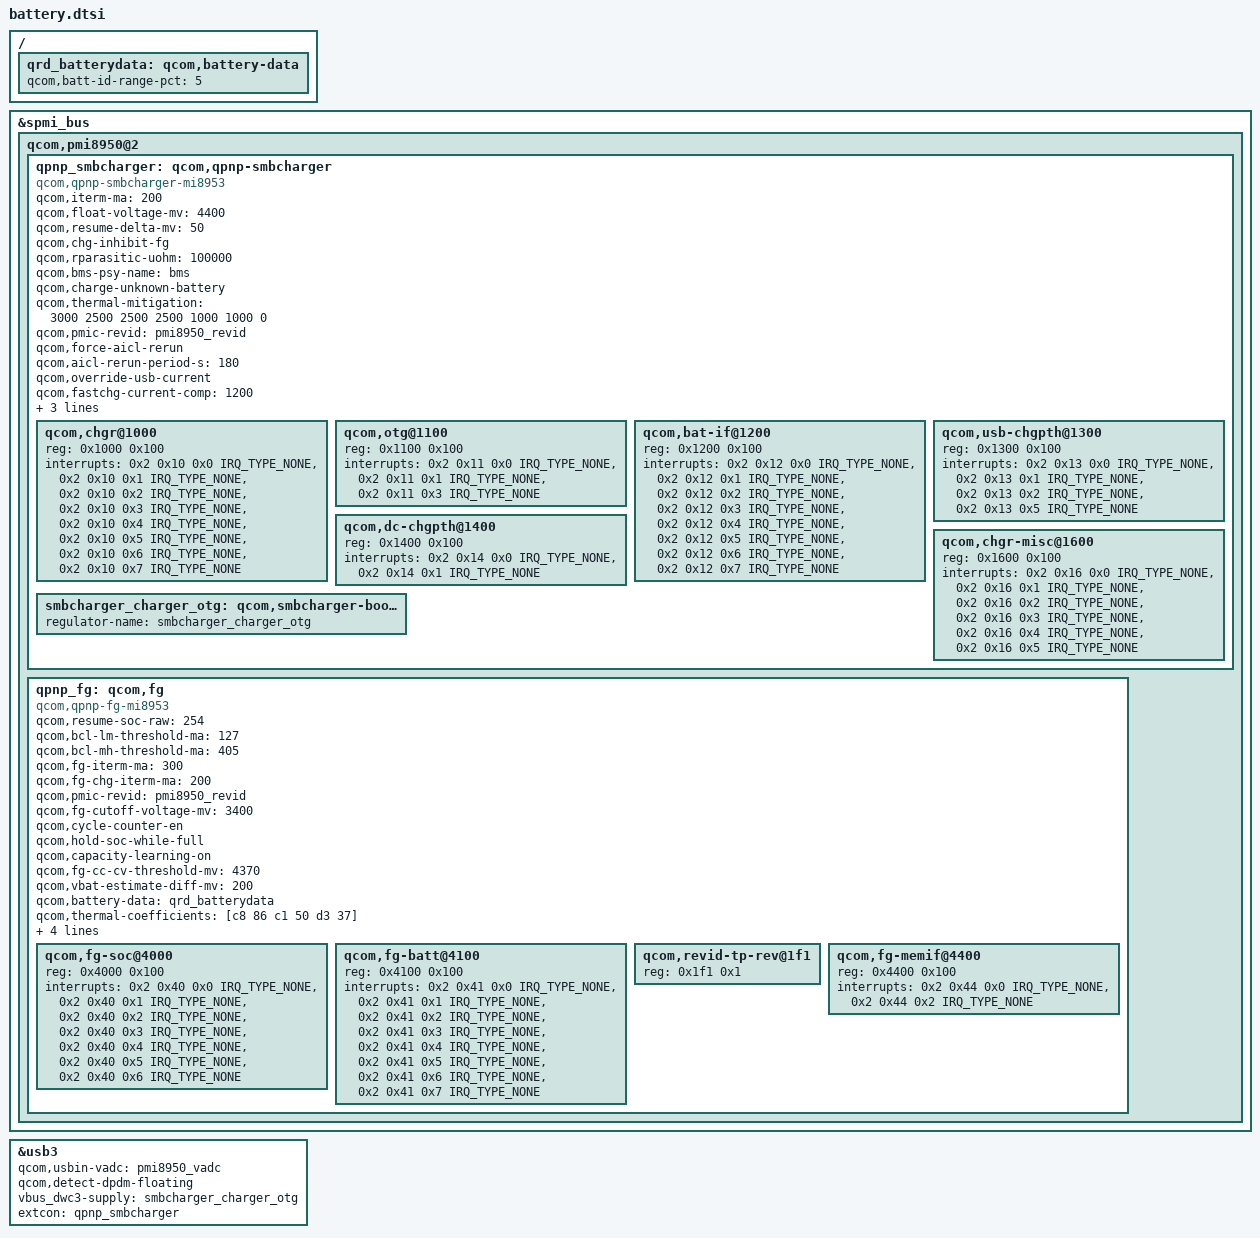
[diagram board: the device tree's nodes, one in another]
/{
	qrd_batterydata: qcom,battery-data {
		qcom,batt-id-range-pct = <5>;
		#include "../common/batterydata/Vince-sunwoda-40Kohm-4000mah.dtsi"
		#include "../common/batterydata/Vince-desay-24Kohm-4000mAh.dtsi"
		#include "../common/batterydata/Vince-coslight-50Kohm-4000mah.dtsi"
		/delete-node/ qcom,qrd_msm8937_sku1_2920mah;
	};
};

&spmi_bus {
	qcom,pmi8950@2 {
		qpnp_smbcharger: qcom,qpnp-smbcharger {
			compatible = "qcom,qpnp-smbcharger-mi8953";
			#address-cells = <1>;
			#size-cells = <1>;

			qcom,iterm-ma = <200>;
			qcom,float-voltage-mv = <4400>;
			qcom,resume-delta-mv = <50>;
			qcom,chg-inhibit-fg;
			qcom,rparasitic-uohm = <100000>;
			qcom,bms-psy-name = "bms";
			qcom,charge-unknown-battery;
			qcom,thermal-mitigation = <3000 2500 2500 2500 1000 1000 0>;
			/delete-property/ qcom,parallel-usb-min-current-ma;
			/delete-property/ qcom,parallel-usb-9v-min-current-ma;
			/delete-property/ qcom,parallel-allowed-lowering-ma;
			qcom,pmic-revid = <&pmi8950_revid>;
			qcom,force-aicl-rerun;
			qcom,aicl-rerun-period-s = <180>;
			qcom,override-usb-current;
			qcom,fastchg-current-comp = <1200>;
			qcom,float-voltage-comp = <15>;
			/delete-property/ qcom,autoadjust-vfloat;
			dpdm-supply = <&qusb_phy>;

			qcom,chgr@1000 {
				reg = <0x1000 0x100>;
				interrupts =	<0x2 0x10 0x0 IRQ_TYPE_NONE>,
						<0x2 0x10 0x1 IRQ_TYPE_NONE>,
						<0x2 0x10 0x2 IRQ_TYPE_NONE>,
						<0x2 0x10 0x3 IRQ_TYPE_NONE>,
						<0x2 0x10 0x4 IRQ_TYPE_NONE>,
						<0x2 0x10 0x5 IRQ_TYPE_NONE>,
						<0x2 0x10 0x6 IRQ_TYPE_NONE>,
						<0x2 0x10 0x7 IRQ_TYPE_NONE>;

				interrupt-names =	"chg-error",
							"chg-inhibit",
							"chg-prechg-sft",
							"chg-complete-chg-sft",
							"chg-p2f-thr",
							"chg-rechg-thr",
							"chg-taper-thr",
							"chg-tcc-thr";
			};

			qcom,otg@1100 {
				reg = <0x1100 0x100>;
				interrupts =	<0x2 0x11 0x0 IRQ_TYPE_NONE>,
						<0x2 0x11 0x1 IRQ_TYPE_NONE>,
						<0x2 0x11 0x3 IRQ_TYPE_NONE>;
				interrupt-names =	"otg-fail",
							"otg-oc",
						"usbid-change";
			};

			qcom,bat-if@1200 {
				reg = <0x1200 0x100>;
				interrupts =	<0x2 0x12 0x0 IRQ_TYPE_NONE>,
						<0x2 0x12 0x1 IRQ_TYPE_NONE>,
						<0x2 0x12 0x2 IRQ_TYPE_NONE>,
						<0x2 0x12 0x3 IRQ_TYPE_NONE>,
						<0x2 0x12 0x4 IRQ_TYPE_NONE>,
						<0x2 0x12 0x5 IRQ_TYPE_NONE>,
						<0x2 0x12 0x6 IRQ_TYPE_NONE>,
						<0x2 0x12 0x7 IRQ_TYPE_NONE>;

				interrupt-names =	"batt-hot",
							"batt-warm",
							"batt-cold",
							"batt-cool",
						"batt-ov",
							"batt-low",
							"batt-missing",
							"batt-term-missing";
			};

			qcom,usb-chgpth@1300 {
				reg = <0x1300 0x100>;
				interrupts =	<0x2 0x13 0x0 IRQ_TYPE_NONE>,
						<0x2 0x13 0x1 IRQ_TYPE_NONE>,
						<0x2 0x13 0x2 IRQ_TYPE_NONE>,
						<0x2 0x13 0x5 IRQ_TYPE_NONE>;

				interrupt-names =	"usbin-uv",
						"usbin-ov",
							"usbin-src-det",
							"aicl-done";
			};

			qcom,dc-chgpth@1400 {
				reg = <0x1400 0x100>;
				interrupts =	<0x2 0x14 0x0 IRQ_TYPE_NONE>,
						<0x2 0x14 0x1 IRQ_TYPE_NONE>;
				interrupt-names =	"dcin-uv",
							"dcin-ov";
			};

			qcom,chgr-misc@1600 {
				reg = <0x1600 0x100>;
				interrupts =	<0x2 0x16 0x0 IRQ_TYPE_NONE>,
						<0x2 0x16 0x1 IRQ_TYPE_NONE>,
						<0x2 0x16 0x2 IRQ_TYPE_NONE>,
						<0x2 0x16 0x3 IRQ_TYPE_NONE>,
						<0x2 0x16 0x4 IRQ_TYPE_NONE>,
						<0x2 0x16 0x5 IRQ_TYPE_NONE>;

				interrupt-names =	"power-ok",
							"temp-shutdown",
							"wdog-timeout",
							"flash-fail",
							"otst2",
							"otst3";
			};

			smbcharger_charger_otg: qcom,smbcharger-boost-otg {
				regulator-name = "smbcharger_charger_otg";
			};
		};

		qpnp_fg: qcom,fg {
			compatible = "qcom,qpnp-fg-mi8953";
			#address-cells = <1>;
			#size-cells = <1>;
			/delete-property/ qcom,resume-soc;
			qcom,resume-soc-raw = <254>;
			status = "okay";
			qcom,bcl-lm-threshold-ma = <127>;
			qcom,bcl-mh-threshold-ma = <405>;
			qcom,fg-iterm-ma = <300>;
			qcom,fg-chg-iterm-ma = <200>;
			qcom,pmic-revid = <&pmi8950_revid>;
			qcom,fg-cutoff-voltage-mv = <3400>;
			qcom,cycle-counter-en;
			qcom,hold-soc-while-full;
			qcom,capacity-learning-on;
			qcom,fg-cc-cv-threshold-mv =<4370>;
			qcom,vbat-estimate-diff-mv = <200>;

			qcom,fg-soc@4000 {
			status = "okay";
				reg = <0x4000 0x100>;
				interrupts =	<0x2 0x40 0x0 IRQ_TYPE_NONE>,
						<0x2 0x40 0x1 IRQ_TYPE_NONE>,
						<0x2 0x40 0x2 IRQ_TYPE_NONE>,
						<0x2 0x40 0x3 IRQ_TYPE_NONE>,
						<0x2 0x40 0x4 IRQ_TYPE_NONE>,
						<0x2 0x40 0x5 IRQ_TYPE_NONE>,
						<0x2 0x40 0x6 IRQ_TYPE_NONE>;

				interrupt-names =	"high-soc",
							"low-soc",
							"full-soc",
							"empty-soc",
							"delta-soc",
							"first-est-done",
							"update-soc";
			};

			qcom,fg-batt@4100 {
				reg = <0x4100 0x100>;
				interrupts =	<0x2 0x41 0x0 IRQ_TYPE_NONE>,
						<0x2 0x41 0x1 IRQ_TYPE_NONE>,
						<0x2 0x41 0x2 IRQ_TYPE_NONE>,
						<0x2 0x41 0x3 IRQ_TYPE_NONE>,
						<0x2 0x41 0x4 IRQ_TYPE_NONE>,
						<0x2 0x41 0x5 IRQ_TYPE_NONE>,
						<0x2 0x41 0x6 IRQ_TYPE_NONE>,
						<0x2 0x41 0x7 IRQ_TYPE_NONE>;

				interrupt-names =	"soft-cold",
							"soft-hot",
							"vbatt-low",
							"batt-ided",
							"batt-id-req",
							"batt-unknown",
							"batt-missing",
							"batt-match";
			};

			qcom,revid-tp-rev@1f1 {
				reg = <0x1f1 0x1>;
			};

			qcom,fg-memif@4400 {
				status = "okay";
				reg = <0x4400 0x100>;
				interrupts =	<0x2 0x44 0x0 IRQ_TYPE_NONE>,
						<0x2 0x44 0x2 IRQ_TYPE_NONE>;

				interrupt-names =	"mem-avail",
							"data-rcvry-sug";
			};
		};
	};
};

&qpnp_smbcharger{
	qcom,battery-data = <&qrd_batterydata>;
	/delete-property/ qcom,external-typec;
	/delete-property/ qcom,typec-psy-name;
	status = "okay";
};

&qpnp_fg {
	qcom,battery-data = <&qrd_batterydata>;
	qcom,thermal-coefficients = [c8 86 c1 50 d3 37];
	qcom,cold-bat-decidegc = <0>;
	qcom,cool-bat-decidegc = <150>;
	qcom,warm-bat-decidegc = <450>;
	qcom,bad-battery-detection-enable;
	qcom,hold-soc-while-full;
};

&usb3 {
	qcom,usbin-vadc = <&pmi8950_vadc>;
	qcom,detect-dpdm-floating;
	vbus_dwc3-supply = <&smbcharger_charger_otg>;
	extcon = <&qpnp_smbcharger>;
};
